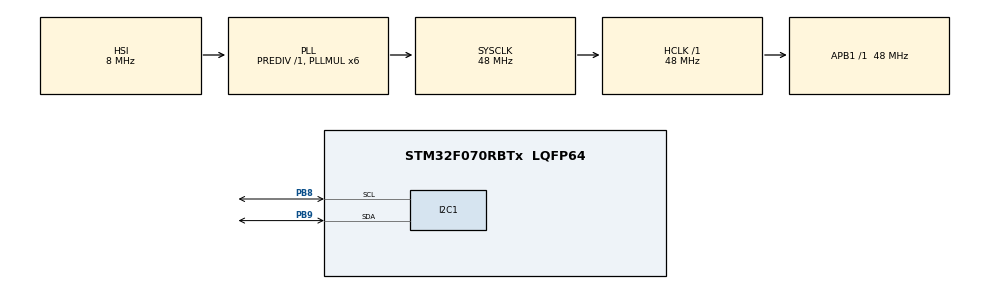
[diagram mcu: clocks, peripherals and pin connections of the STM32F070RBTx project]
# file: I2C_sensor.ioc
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Mcu.Family=STM32F0
Mcu.Name=STM32F070RBTx
Mcu.Package=LQFP64
PA13.Mode=Serial_Wire
PA13.Signal=SYS_SWDIO
PA14.Mode=Serial_Wire
PA14.Signal=SYS_SWCLK
PB8.Mode=I2C
PB8.Signal=I2C1_SCL
PB9.Mode=I2C
PB9.Signal=I2C1_SDA
ProjectManager.HeapSize=0x200
ProjectManager.StackSize=0x400
ProjectManager.TargetToolchain=STM32CubeIDE
RCC.AHBFreq_Value=48000000
RCC.APB1Freq_Value=48000000
RCC.APB1TimFreq_Value=48000000
RCC.HCLKFreq_Value=48000000
RCC.PLLMUL=RCC_PLL_MUL6
RCC.SYSCLKFreq_VALUE=48000000
RCC.SYSCLKSource=RCC_SYSCLKSOURCE_PLLCLK
board=NUCLEO-F070RB

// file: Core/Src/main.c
/* USER CODE BEGIN Header */
/**
 ******************************************************************************
 * @file           : main.c
 * @brief          : Main program body
 ******************************************************************************
 * @attention
 *
 * Copyright (c) 2022 STMicroelectronics.
 * All rights reserved.
 *
 * This software is licensed under terms that can be found in the LICENSE file
 * in the root directory of this software component.
 * If no LICENSE file comes with this software, it is provided AS-IS.
 *
 ******************************************************************************
 */
/* USER CODE END Header */
#include "main.h"

/* USER CODE BEGIN Includes */
#include "sht31.h"
/* USER CODE END Includes */

extern I2C_HandleTypeDef hi2c1;

void SystemClock_Config(void);
static void MX_GPIO_Init(void);
static void MX_I2C1_Init(void);

/* USER CODE BEGIN 0 */
typedef enum psEnum {
	high_mps_05, medium_mps_05, low_mps_05,

	high_mps_1, medium_mps_1, low_mps_1,

	high_mps_2, medium_mps_2, low_mps_2,

	high_mps_4, medium_mps_4, low_mps_4,

	high_mps_10, medium_mps_10, low_mps_10
};

typedef enum ssEnum {
	high_enable,
	medium_enable,
	low_enable,
	high_disabled,
	medium_disabled,
	low_disabled
};
/* USER CODE END 0 */

int main(void) {

	/* MCU Configuration--------------------------------------------------------*/

	/* Reset of all peripherals, Initializes the Flash interface and the Systick. */
	HAL_Init();

	/* Configure the system clock */
	SystemClock_Config();

	/* Initialize all configured peripherals */
	MX_GPIO_Init();
	MX_I2C1_Init();
	/* USER CODE BEGIN 2 */

//	softReset();
//	HAL_Delay(1000);
//	startPeriodicShot('d', high_disabled);
//	HAL_Delay(1000);
	/* USER CODE END 2 */

	/* Infinite loop */
	/* USER CODE BEGIN WHILE */

	while (1) {
//		readPeriodicShot();
//		heaterEnable(buf, sizeof(buf));
//		//READ NEW DATA
//		readPeriodicShot();
//		heaterDisabled(buf, sizeof(buf));

		/* USER CODE END WHILE */

	}
}

void SystemClock_Config(void) {
	RCC_OscInitTypeDef RCC_OscInitStruct = { 0 };
	RCC_ClkInitTypeDef RCC_ClkInitStruct = { 0 };
	RCC_PeriphCLKInitTypeDef PeriphClkInit = { 0 };

	/** Initializes the RCC Oscillators according to the specified parameters
	 * in the RCC_OscInitTypeDef structure.
	 */
	RCC_OscInitStruct.OscillatorType = RCC_OSCILLATORTYPE_HSI;
	RCC_OscInitStruct.HSIState = RCC_HSI_ON;
	RCC_OscInitStruct.HSICalibrationValue = RCC_HSICALIBRATION_DEFAULT;
	RCC_OscInitStruct.PLL.PLLState = RCC_PLL_ON;
	RCC_OscInitStruct.PLL.PLLSource = RCC_PLLSOURCE_HSI;
	RCC_OscInitStruct.PLL.PLLMUL = RCC_PLL_MUL6;
	RCC_OscInitStruct.PLL.PREDIV = RCC_PREDIV_DIV1;
	if (HAL_RCC_OscConfig(&RCC_OscInitStruct) != HAL_OK) {
		Error_Handler();
	}

	/** Initializes the CPU, AHB and APB buses clocks
	 */
	RCC_ClkInitStruct.ClockType = RCC_CLOCKTYPE_HCLK | RCC_CLOCKTYPE_SYSCLK
			| RCC_CLOCKTYPE_PCLK1;
	RCC_ClkInitStruct.SYSCLKSource = RCC_SYSCLKSOURCE_PLLCLK;
	RCC_ClkInitStruct.AHBCLKDivider = RCC_SYSCLK_DIV1;
	RCC_ClkInitStruct.APB1CLKDivider = RCC_HCLK_DIV1;

	if (HAL_RCC_ClockConfig(&RCC_ClkInitStruct, FLASH_LATENCY_1) != HAL_OK) {
		Error_Handler();
	}
	PeriphClkInit.PeriphClockSelection = RCC_PERIPHCLK_I2C1;
	PeriphClkInit.I2c1ClockSelection = RCC_I2C1CLKSOURCE_HSI;
	if (HAL_RCCEx_PeriphCLKConfig(&PeriphClkInit) != HAL_OK) {
		Error_Handler();
	}
}

static void MX_I2C1_Init(void) {

	hi2c1.Instance = I2C1;
	hi2c1.Init.Timing = 0x2000090E;
	hi2c1.Init.OwnAddress1 = 0;
	hi2c1.Init.AddressingMode = I2C_ADDRESSINGMODE_7BIT;
	hi2c1.Init.DualAddressMode = I2C_DUALADDRESS_DISABLE;
	hi2c1.Init.OwnAddress2 = 0;
	hi2c1.Init.OwnAddress2Masks = I2C_OA2_NOMASK;
	hi2c1.Init.GeneralCallMode = I2C_GENERALCALL_DISABLE;
	hi2c1.Init.NoStretchMode = I2C_NOSTRETCH_DISABLE;
	if (HAL_I2C_Init(&hi2c1) != HAL_OK) {
		Error_Handler();
	}

	/** Configure Analogue filter
	 */
	if (HAL_I2CEx_ConfigAnalogFilter(&hi2c1, I2C_ANALOGFILTER_ENABLE)
			!= HAL_OK) {
		Error_Handler();
	}

	/** Configure Digital filter
	 */
	if (HAL_I2CEx_ConfigDigitalFilter(&hi2c1, 0) != HAL_OK) {
		Error_Handler();
	}

}

static void MX_GPIO_Init(void) {

	/* GPIO Ports Clock Enable */
	__HAL_RCC_GPIOA_CLK_ENABLE();
	__HAL_RCC_GPIOB_CLK_ENABLE();

}

void Error_Handler(void) {
	__disable_irq();
	while (1) {
	}
}
